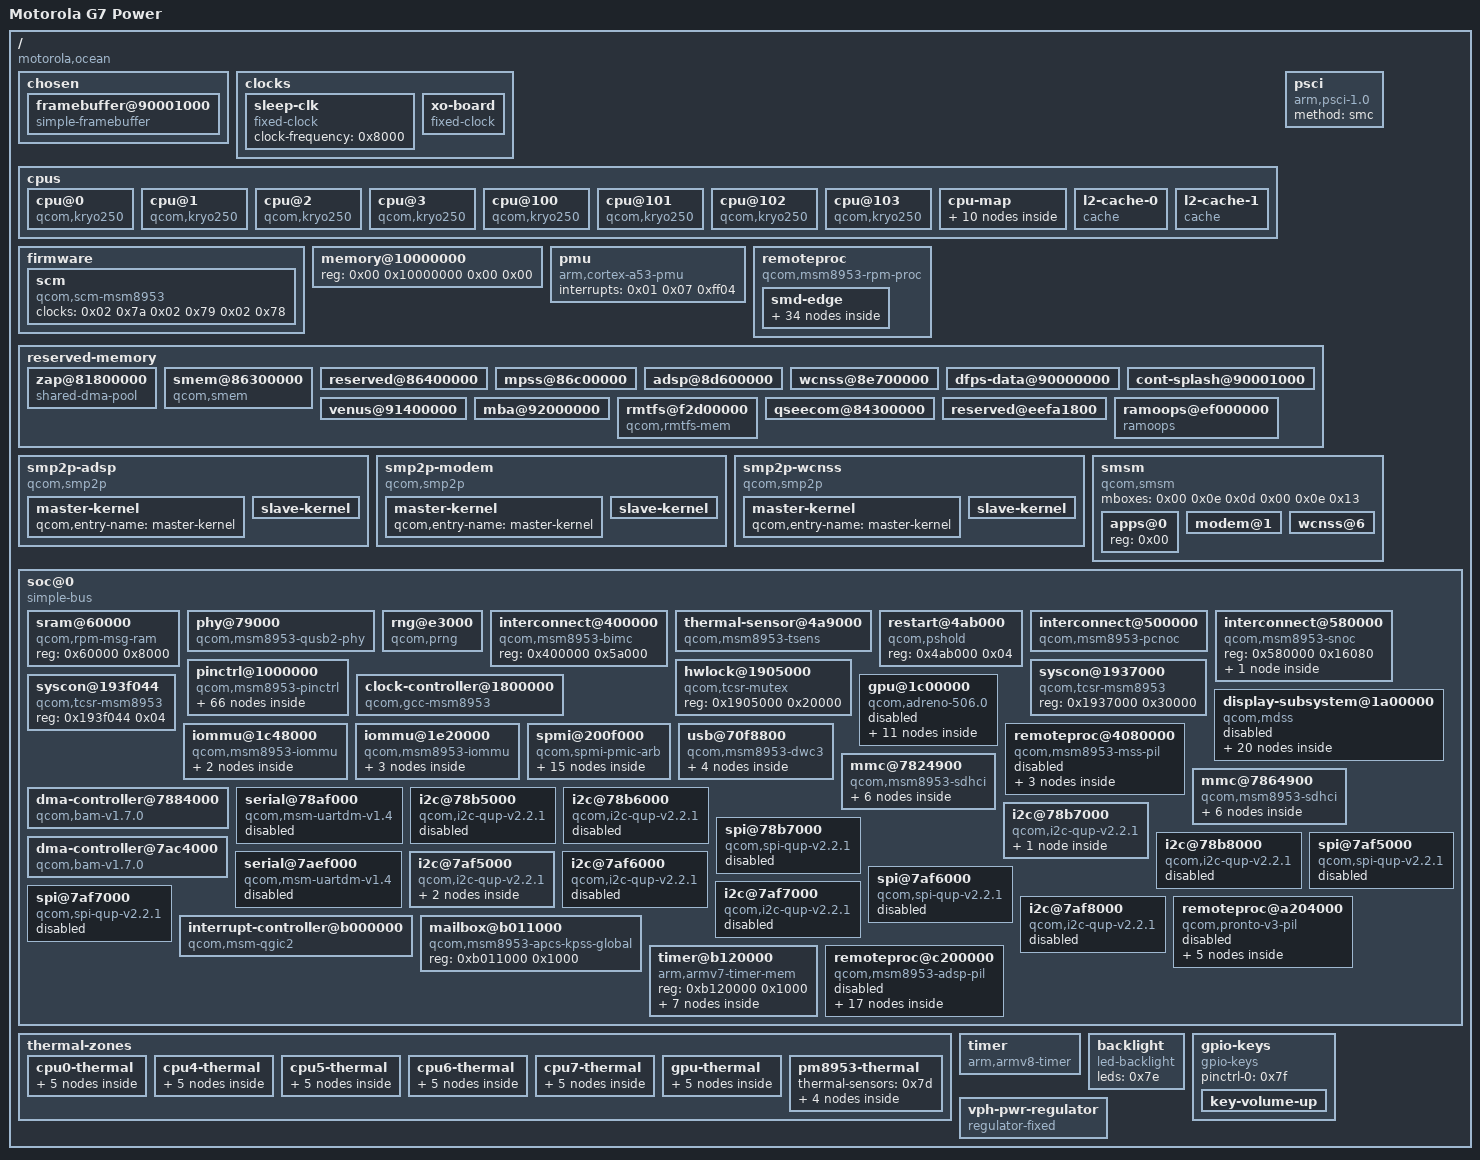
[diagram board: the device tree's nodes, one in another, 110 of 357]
/dts-v1/;

/ {
	interrupt-parent = <0x01>;
	#address-cells = <0x02>;
	#size-cells = <0x02>;
	model = "Motorola G7 Power";
	compatible = "motorola,ocean\0qcom,sdm632";
	chassis-type = "handset";
	qcom,msm-id = <0x15d 0x00>;
	qcom,board-id = <0x141 0xc100>;
	qcom,pmic-id = <0x10016 0x25 0x00 0x00>;

	chosen {
		#address-cells = <0x02>;
		#size-cells = <0x02>;
		ranges;

		framebuffer@90001000 {
			compatible = "simple-framebuffer";
			reg = <0x00 0x90001000 0x00 0x321900>;
			width = <0x2d0>;
			height = <0x5f0>;
			stride = <0x870>;
			format = "r8g8b8";
			power-domains = <0x02 0x02>;
			clocks = <0x02 0x81 0x02 0x82 0x02 0x8a 0x02 0x87 0x02 0x83 0x02 0x88 0x02 0x85>;
		};
	};

	clocks {

		sleep-clk {
			compatible = "fixed-clock";
			#clock-cells = <0x00>;
			clock-frequency = <0x8000>;
			phandle = <0x1c>;
		};

		xo-board {
			compatible = "fixed-clock";
			#clock-cells = <0x00>;
			clock-frequency = <0x124f800>;
			clock-output-names = "xo";
			phandle = <0x0f>;
		};
	};

	cpus {
		#address-cells = <0x01>;
		#size-cells = <0x00>;

		cpu@0 {
			device_type = "cpu";
			compatible = "qcom,kryo250";
			reg = <0x00>;
			enable-method = "psci";
			capacity-dmips-mhz = <0x400>;
			interconnects = <0x03 0x00 0x01 0x03 0x06 0x01>;
			next-level-cache = <0x04>;
			#cooling-cells = <0x02>;
			phandle = <0x06>;
		};

		cpu@1 {
			device_type = "cpu";
			compatible = "qcom,kryo250";
			reg = <0x01>;
			enable-method = "psci";
			capacity-dmips-mhz = <0x400>;
			interconnects = <0x03 0x00 0x01 0x03 0x06 0x01>;
			next-level-cache = <0x04>;
			#cooling-cells = <0x02>;
			phandle = <0x07>;
		};

		cpu@2 {
			device_type = "cpu";
			compatible = "qcom,kryo250";
			reg = <0x02>;
			enable-method = "psci";
			capacity-dmips-mhz = <0x400>;
			interconnects = <0x03 0x00 0x01 0x03 0x06 0x01>;
			next-level-cache = <0x04>;
			#cooling-cells = <0x02>;
			phandle = <0x08>;
		};

		cpu@3 {
			device_type = "cpu";
			compatible = "qcom,kryo250";
			reg = <0x03>;
			enable-method = "psci";
			capacity-dmips-mhz = <0x400>;
			interconnects = <0x03 0x00 0x01 0x03 0x06 0x01>;
			next-level-cache = <0x04>;
			#cooling-cells = <0x02>;
			phandle = <0x09>;
		};

		cpu@100 {
			device_type = "cpu";
			compatible = "qcom,kryo250";
			reg = <0x100>;
			enable-method = "psci";
			capacity-dmips-mhz = <0x7bc>;
			interconnects = <0x03 0x00 0x01 0x03 0x06 0x01>;
			next-level-cache = <0x05>;
			#cooling-cells = <0x02>;
			phandle = <0x0a>;
		};

		cpu@101 {
			device_type = "cpu";
			compatible = "qcom,kryo250";
			reg = <0x101>;
			enable-method = "psci";
			capacity-dmips-mhz = <0x7bc>;
			interconnects = <0x03 0x00 0x01 0x03 0x06 0x01>;
			next-level-cache = <0x05>;
			#cooling-cells = <0x02>;
			phandle = <0x0b>;
		};

		cpu@102 {
			device_type = "cpu";
			compatible = "qcom,kryo250";
			reg = <0x102>;
			enable-method = "psci";
			capacity-dmips-mhz = <0x7bc>;
			interconnects = <0x03 0x00 0x01 0x03 0x06 0x01>;
			next-level-cache = <0x05>;
			#cooling-cells = <0x02>;
			phandle = <0x0c>;
		};

		cpu@103 {
			device_type = "cpu";
			compatible = "qcom,kryo250";
			reg = <0x103>;
			enable-method = "psci";
			capacity-dmips-mhz = <0x7bc>;
			interconnects = <0x03 0x00 0x01 0x03 0x06 0x01>;
			next-level-cache = <0x05>;
			#cooling-cells = <0x02>;
			phandle = <0x0d>;
		};

		cpu-map {

			cluster0 {

				core0 {
					cpu = <0x06>;
				};

				core1 {
					cpu = <0x07>;
				};

				core2 {
					cpu = <0x08>;
				};

				core3 {
					cpu = <0x09>;
				};
			};

			cluster1 {

				core0 {
					cpu = <0x0a>;
				};

				core1 {
					cpu = <0x0b>;
				};

				core2 {
					cpu = <0x0c>;
				};

				core3 {
					cpu = <0x0d>;
				};
			};
		};

		l2-cache-0 {
			compatible = "cache";
			cache-level = <0x02>;
			cache-unified;
			phandle = <0x04>;
		};

		l2-cache-1 {
			compatible = "cache";
			cache-level = <0x02>;
			cache-unified;
			phandle = <0x05>;
		};
	};

	firmware {

		scm {
			compatible = "qcom,scm-msm8953\0qcom,scm";
			clocks = <0x02 0x7a 0x02 0x79 0x02 0x78>;
			clock-names = "core\0bus\0iface";
			#reset-cells = <0x01>;
		};
	};

	memory@10000000 {
		device_type = "memory";
		reg = <0x00 0x10000000 0x00 0x00>;
	};

	pmu {
		compatible = "arm,cortex-a53-pmu";
		interrupts = <0x01 0x07 0xff04>;
	};

	psci {
		compatible = "arm,psci-1.0";
		method = "smc";
	};

	remoteproc {
		compatible = "qcom,msm8953-rpm-proc\0qcom,rpm-proc";

		smd-edge {
			interrupts = <0x00 0xa8 0x01>;
			mboxes = <0x0e 0x00>;
			qcom,smd-edge = <0x0f>;

			rpm-requests {
				compatible = "qcom,rpm-msm8953\0qcom,smd-rpm";
				qcom,smd-channels = "rpm_requests";

				clock-controller {
					compatible = "qcom,rpmcc-msm8953\0qcom,rpmcc";
					clocks = <0x0f>;
					clock-names = "xo";
					#clock-cells = <0x01>;
					phandle = <0x1b>;
				};

				power-controller {
					compatible = "qcom,msm8953-rpmpd";
					#power-domain-cells = <0x01>;
					operating-points-v2 = <0x10>;
					phandle = <0x34>;

					opp-table {
						compatible = "operating-points-v2";
						phandle = <0x10>;

						opp1 {
							opp-level = <0x10>;
						};

						opp2 {
							opp-level = <0x20>;
						};

						opp3 {
							opp-level = <0x30>;
							phandle = <0x2a>;
						};

						opp4 {
							opp-level = <0x40>;
							phandle = <0x2b>;
						};

						opp5 {
							opp-level = <0x80>;
							phandle = <0x2c>;
						};

						opp6 {
							opp-level = <0xc0>;
							phandle = <0x2d>;
						};

						opp7 {
							opp-level = <0x100>;
							phandle = <0x2e>;
						};

						opp8 {
							opp-level = <0x140>;
							phandle = <0x2f>;
						};

						opp9 {
							opp-level = <0x180>;
							phandle = <0x30>;
						};
					};
				};

				regulators {
					compatible = "qcom,rpm-pm8953-regulators";
					vdd_l1-supply = <0x11>;
					vdd_l2_l3-supply = <0x11>;
					vdd_l4_l5_l6_l7_l16_l19-supply = <0x12>;
					vdd_l8_l11_l12_l13_l14_l15-supply = <0x13>;
					vdd_l9_l10_l17_l18_l22-supply = <0x13>;

					s3 {
						regulator-min-microvolt = <0xf03c0>;
						regulator-max-microvolt = <0x12ebc0>;
						phandle = <0x11>;
					};

					s4 {
						regulator-min-microvolt = <0xfcee0>;
						regulator-max-microvolt = <0x1f20c0>;
						phandle = <0x12>;
					};

					l1 {
						regulator-min-microvolt = <0xee098>;
						regulator-max-microvolt = <0x100590>;
					};

					l2 {
						regulator-min-microvolt = <0xee098>;
						regulator-max-microvolt = <0x11edd8>;
					};

					l3 {
						regulator-min-microvolt = <0xe1d48>;
						regulator-max-microvolt = <0xe1d48>;
						regulator-allow-set-load;
						phandle = <0x17>;
					};

					l5 {
						regulator-min-microvolt = <0x1b7740>;
						regulator-max-microvolt = <0x1b7740>;
						phandle = <0x44>;
					};

					l6 {
						regulator-min-microvolt = <0x1b7740>;
						regulator-max-microvolt = <0x1b7740>;
						regulator-always-on;
						regulator-boot-on;
					};

					l7 {
						regulator-min-microvolt = <0x1b7740>;
						regulator-max-microvolt = <0x1cfde0>;
						phandle = <0x18>;
					};

					l8 {
						regulator-min-microvolt = <0x2c4020>;
						regulator-max-microvolt = <0x2c4020>;
						phandle = <0x43>;
					};

					l9 {
						regulator-min-microvolt = <0x2dc6c0>;
						regulator-max-microvolt = <0x325aa0>;
					};

					l10 {
						regulator-min-microvolt = <0x2ab980>;
						regulator-max-microvolt = <0x2dc6c0>;
					};

					l11 {
						regulator-min-microvolt = <0x2d0370>;
						regulator-max-microvolt = <0x2d0370>;
						phandle = <0x4e>;
					};

					l12 {
						regulator-min-microvolt = <0x1b7740>;
						regulator-max-microvolt = <0x2d0370>;
						phandle = <0x4f>;
					};

					l13 {
						regulator-min-microvolt = <0x2faf08>;
						regulator-max-microvolt = <0x2faf08>;
						phandle = <0x19>;
					};

					l16 {
						regulator-min-microvolt = <0x1b7740>;
						regulator-max-microvolt = <0x1b7740>;
					};

					l17 {
						regulator-min-microvolt = <0x2b7cd0>;
						regulator-max-microvolt = <0x2b7cd0>;
					};

					l18 {
						regulator-min-microvolt = <0x1b7740>;
						regulator-max-microvolt = <0x2932e0>;
						regulator-always-on;
						regulator-boot-on;
					};

					l19 {
						regulator-min-microvolt = <0x124f80>;
						regulator-max-microvolt = <0x149970>;
					};

					l22 {
						regulator-min-microvolt = <0x1b7740>;
						regulator-max-microvolt = <0x1b7740>;
						regulator-always-on;
					};

					l23 {
						regulator-min-microvolt = <0xee098>;
						regulator-max-microvolt = <0x12b128>;
					};
				};
			};
		};
	};

	reserved-memory {
		#address-cells = <0x02>;
		#size-cells = <0x02>;
		ranges;

		zap@81800000 {
			compatible = "shared-dma-pool";
			reg = <0x00 0x81800000 0x00 0x2000>;
			no-map;
			phandle = <0x29>;
		};

		smem@86300000 {
			compatible = "qcom,smem";
			reg = <0x00 0x86300000 0x00 0x100000>;
			qcom,rpm-msg-ram = <0x14>;
			hwlocks = <0x15 0x03>;
			no-map;
		};

		reserved@86400000 {
			reg = <0x00 0x86400000 0x00 0x400000>;
			no-map;
		};

		mpss@86c00000 {
			reg = <0x00 0x86c00000 0x00 0x6a00000>;
			no-map;
			phandle = <0x38>;
		};

		adsp@8d600000 {
			reg = <0x00 0x8d600000 0x00 0x1100000>;
			no-map;
			phandle = <0x73>;
		};

		wcnss@8e700000 {
			reg = <0x00 0x8e700000 0x00 0x700000>;
			no-map;
			phandle = <0x6c>;
		};

		dfps-data@90000000 {
			reg = <0x00 0x90000000 0x00 0x1000>;
			no-map;
		};

		cont-splash@90001000 {
			reg = <0x00 0x90001000 0x00 0x321900>;
			no-map;
		};

		venus@91400000 {
			reg = <0x00 0x91400000 0x00 0x700000>;
			no-map;
		};

		mba@92000000 {
			reg = <0x00 0x92000000 0x00 0x100000>;
			no-map;
			phandle = <0x37>;
		};

		rmtfs@f2d00000 {
			compatible = "qcom,rmtfs-mem";
			reg = <0x00 0xf2d00000 0x00 0x180000>;
			no-map;
			qcom,client-id = <0x01>;
		};

		qseecom@84300000 {
			reg = <0x00 0x84300000 0x00 0x2000000>;
			no-map;
		};

		reserved@eefa1800 {
			reg = <0x00 0xeefa1800 0x00 0x5e800>;
			no-map;
		};

		ramoops@ef000000 {
			compatible = "ramoops";
			reg = <0x00 0xef000000 0x00 0xbf800>;
			console-size = <0x40000>;
			pmsg-size = <0x40000>;
			record-size = <0x3f800>;
		};
	};

	smp2p-adsp {
		compatible = "qcom,smp2p";
		qcom,smem = <0x1bb 0x1ad>;
		interrupts = <0x00 0x123 0x01>;
		mboxes = <0x0e 0x0a>;
		qcom,local-pid = <0x00>;
		qcom,remote-pid = <0x02>;

		master-kernel {
			qcom,entry-name = "master-kernel";
			#qcom,smem-state-cells = <0x01>;
			phandle = <0x74>;
		};

		slave-kernel {
			qcom,entry-name = "slave-kernel";
			interrupt-controller;
			#interrupt-cells = <0x02>;
			phandle = <0x72>;
		};
	};

	smp2p-modem {
		compatible = "qcom,smp2p";
		qcom,smem = <0x1b3 0x1ac>;
		interrupts = <0x00 0x1b 0x01>;
		mboxes = <0x0e 0x0e>;
		qcom,local-pid = <0x00>;
		qcom,remote-pid = <0x01>;

		master-kernel {
			qcom,entry-name = "master-kernel";
			#qcom,smem-state-cells = <0x01>;
			phandle = <0x35>;
		};

		slave-kernel {
			qcom,entry-name = "slave-kernel";
			interrupt-controller;
			#interrupt-cells = <0x02>;
			phandle = <0x33>;
		};
	};

	smp2p-wcnss {
		compatible = "qcom,smp2p";
		qcom,smem = <0x1c3 0x1af>;
		interrupts = <0x00 0x8f 0x01>;
		mboxes = <0x0e 0x12>;
		qcom,local-pid = <0x00>;
		qcom,remote-pid = <0x04>;

		master-kernel {
			qcom,entry-name = "master-kernel";
			#qcom,smem-state-cells = <0x01>;
			phandle = <0x6e>;
		};

		slave-kernel {
			qcom,entry-name = "slave-kernel";
			interrupt-controller;
			#interrupt-cells = <0x02>;
			phandle = <0x6d>;
		};
	};

	smsm {
		compatible = "qcom,smsm";
		#address-cells = <0x01>;
		#size-cells = <0x00>;
		mboxes = <0x00 0x0e 0x0d 0x00 0x0e 0x13>;

		apps@0 {
			reg = <0x00>;
			#qcom,smem-state-cells = <0x01>;
			phandle = <0x71>;
		};

		modem@1 {
			reg = <0x01>;
			interrupts = <0x00 0x1a 0x01>;
			interrupt-controller;
			#interrupt-cells = <0x02>;
		};

		wcnss@6 {
			reg = <0x06>;
			interrupts = <0x00 0x90 0x01>;
			interrupt-controller;
			#interrupt-cells = <0x02>;
		};
	};

	soc@0 {
		#address-cells = <0x01>;
		#size-cells = <0x01>;
		ranges = <0x00 0x00 0x00 0xffffffff>;
		compatible = "simple-bus";

		sram@60000 {
			compatible = "qcom,rpm-msg-ram";
			reg = <0x60000 0x8000>;
			phandle = <0x14>;
		};

		phy@79000 {
			compatible = "qcom,msm8953-qusb2-phy";
			reg = <0x79000 0x180>;
			#phy-cells = <0x00>;
			clocks = <0x02 0xa3 0x02 0x96>;
			clock-names = "cfg_ahb\0ref";
			qcom,tcsr-syscon = <0x16>;
			resets = <0x02 0x02>;
			status = "okay";
			vdd-supply = <0x17>;
			vdda-pll-supply = <0x18>;
			vdda-phy-dpdm-supply = <0x19>;
			phandle = <0x39>;
		};

		rng@e3000 {
			compatible = "qcom,prng";
			reg = <0xe3000 0x1000>;
			clocks = <0x02 0x94>;
			clock-names = "core";
		};

		interconnect@400000 {
			compatible = "qcom,msm8953-bimc";
			reg = <0x400000 0x5a000>;
			#interconnect-cells = <0x02>;
			phandle = <0x03>;
		};

		thermal-sensor@4a9000 {
			compatible = "qcom,msm8953-tsens\0qcom,tsens-v2";
			reg = <0x4a9000 0x1000 0x4a8000 0x1000>;
			#qcom,sensors = <0x10>;
			interrupts = <0x00 0xb8 0x04 0x00 0x13a 0x04>;
			interrupt-names = "uplow\0critical";
			#thermal-sensor-cells = <0x01>;
			phandle = <0x75>;
		};

		restart@4ab000 {
			compatible = "qcom,pshold";
			reg = <0x4ab000 0x04>;
		};

		interconnect@500000 {
			compatible = "qcom,msm8953-pcnoc";
			reg = <0x500000 0x12080>;
			clocks = <0x02 0x91>;
			clock-names = "pcnoc_usb3_axi";
			#interconnect-cells = <0x02>;
			phandle = <0x20>;
		};

		interconnect@580000 {
			compatible = "qcom,msm8953-snoc";
			reg = <0x580000 0x16080>;
			#interconnect-cells = <0x02>;

			interconnect-snoc {
				compatible = "qcom,msm8953-snoc-mm";
				#interconnect-cells = <0x02>;
				phandle = <0x1f>;
			};
		};

		pinctrl@1000000 {
			compatible = "qcom,msm8953-pinctrl";
			reg = <0x1000000 0x300000>;
			interrupts = <0x00 0xd0 0x04>;
			gpio-controller;
			gpio-ranges = <0x1a 0x00 0x00 0x8e>;
			#gpio-cells = <0x02>;
			interrupt-controller;
			#interrupt-cells = <0x02>;
			gpio-reserved-ranges = <0x60 0x04>;
			phandle = <0x1a>;

			uart-console-active-state {
				pins = "gpio4\0gpio5";
				function = "blsp_uart2";
				drive-strength = <0x02>;
				bias-disable;
			};

			uart-console-sleep-state {
				pins = "gpio4\0gpio5";
				function = "blsp_uart2";
				drive-strength = <0x02>;
				bias-pull-down;
			};

			sdc1-clk-on-state {
				pins = "sdc1_clk";
				bias-disable;
				drive-strength = <0x10>;
				phandle = <0x3b>;
			};

			sdc1-clk-off-state {
				pins = "sdc1_clk";
				bias-disable;
				drive-strength = <0x02>;
				phandle = <0x3f>;
			};

			sdc1-cmd-on-state {
				pins = "sdc1_cmd";
				bias-disable;
				drive-strength = <0x0a>;
				phandle = <0x3c>;
			};

			sdc1-cmd-off-state {
				pins = "sdc1_cmd";
				bias-disable;
				drive-strength = <0x02>;
				phandle = <0x40>;
			};

			sdc1-data-on-state {
				pins = "sdc1_data";
				bias-pull-up;
				drive-strength = <0x0a>;
				phandle = <0x3d>;
			};

			sdc1-data-off-state {
				pins = "sdc1_data";
				bias-pull-up;
				drive-strength = <0x02>;
				phandle = <0x41>;
			};

			sdc1-rclk-on-state {
				pins = "sdc1_rclk";
				bias-pull-down;
				phandle = <0x3e>;
			};

			sdc1-rclk-off-state {
				pins = "sdc1_rclk";
				bias-pull-down;
				phandle = <0x42>;
			};

			sdc2-clk-on-state {
				pins = "sdc2_clk";
				drive-strength = <0x10>;
				bias-disable;
				phandle = <0x46>;
			};

			sdc2-clk-off-state {
				pins = "sdc2_clk";
				bias-disable;
				drive-strength = <0x02>;
				phandle = <0x4a>;
			};

			sdc2-cmd-on-state {
				pins = "sdc2_cmd";
				bias-pull-up;
				drive-strength = <0x0a>;
				phandle = <0x47>;
			};

			sdc2-cmd-off-state {
				pins = "sdc2_cmd";
				bias-pull-up;
				drive-strength = <0x02>;
				phandle = <0x4b>;
			};

			sdc2-data-on-state {
				pins = "sdc2_data";
				bias-pull-up;
				drive-strength = <0x0a>;
				phandle = <0x48>;
			};

			sdc2-data-off-state {
				pins = "sdc2_data";
				bias-pull-up;
				drive-strength = <0x02>;
				phandle = <0x4c>;
			};

			cd-on-state {
				pins = "gpio133";
				function = "gpio";
				drive-strength = <0x02>;
				bias-pull-up;
				phandle = <0x49>;
			};

			cd-off-state {
				pins = "gpio133";
				function = "gpio";
				drive-strength = <0x02>;
				bias-disable;
				phandle = <0x4d>;
			};

			gpio-key-default-state {
				pins = "gpio85";
				function = "gpio";
				drive-strength = <0x02>;
				bias-pull-up;
				phandle = <0x7f>;
			};

			i2c-1-default-state {
				pins = "gpio2\0gpio3";
				function = "blsp_i2c1";
				drive-strength = <0x02>;
				bias-disable;
				phandle = <0x51>;
			};

			i2c-1-sleep-state {
				pins = "gpio2\0gpio3";
				function = "gpio";
				drive-strength = <0x02>;
				bias-disable;
				phandle = <0x52>;
			};

			i2c-2-default-state {
				pins = "gpio6\0gpio7";
				function = "blsp_i2c2";
				drive-strength = <0x02>;
				bias-disable;
				phandle = <0x53>;
			};

			i2c-2-sleep-state {
				pins = "gpio6\0gpio7";
				function = "gpio";
				drive-strength = <0x02>;
				bias-disable;
				phandle = <0x54>;
			};

			i2c-3-default-state {
				pins = "gpio10\0gpio11";
				function = "blsp_i2c3";
				drive-strength = <0x02>;
				bias-disable;
				phandle = <0x55>;
			};

			i2c-3-sleep-state {
				pins = "gpio10\0gpio11";
				function = "gpio";
				drive-strength = <0x02>;
				bias-disable;
				phandle = <0x56>;
			};

			i2c-4-default-state {
				pins = "gpio14\0gpio15";
				function = "blsp_i2c4";
				drive-strength = <0x02>;
				bias-disable;
				phandle = <0x5a>;
			};

			i2c-4-sleep-state {
				pins = "gpio14\0gpio15";
				function = "gpio";
				drive-strength = <0x02>;
				bias-disable;
				phandle = <0x5b>;
			};

			i2c-5-default-state {
				pins = "gpio18\0gpio19";
				function = "blsp_i2c5";
				drive-strength = <0x02>;
				bias-disable;
				phandle = <0x5e>;
			};

			i2c-5-sleep-state {
				pins = "gpio18\0gpio19";
				function = "gpio";
				drive-strength = <0x02>;
				bias-disable;
				phandle = <0x5f>;
			};

			i2c-6-default-state {
				pins = "gpio22\0gpio23";
				function = "blsp_i2c6";
				drive-strength = <0x02>;
				bias-disable;
				phandle = <0x62>;
			};

			i2c-6-sleep-state {
				pins = "gpio22\0gpio23";
				function = "gpio";
				drive-strength = <0x02>;
				bias-disable;
				phandle = <0x63>;
			};

			i2c-7-default-state {
				pins = "gpio135\0gpio136";
				function = "blsp_i2c7";
				drive-strength = <0x02>;
				bias-disable;
				phandle = <0x66>;
			};

			i2c-7-sleep-state {
				pins = "gpio135\0gpio136";
				function = "gpio";
				drive-strength = <0x02>;
				bias-disable;
				phandle = <0x67>;
			};

			i2c-8-default-state {
				pins = "gpio98\0gpio99";
				function = "blsp_i2c8";
				drive-strength = <0x02>;
				bias-disable;
				phandle = <0x6a>;
			};

			i2c-8-sleep-state {
				pins = "gpio98\0gpio99";
				function = "gpio";
				drive-strength = <0x02>;
				bias-disable;
				phandle = <0x6b>;
			};

			spi-3-default-state {
				phandle = <0x57>;

				cs-pins {
					pins = "gpio10";
					function = "blsp_spi3";
					drive-strength = <0x02>;
					bias-disable;
				};

				spi-pins {
					pins = "gpio8\0gpio9\0gpio11";
					function = "blsp_spi3";
					drive-strength = <0x0c>;
					bias-disable;
				};
			};

			spi-3-sleep-state {
				phandle = <0x58>;

				cs-pins {
					pins = "gpio10";
					function = "gpio";
					drive-strength = <0x02>;
					bias-disable;
				};

				spi-pins {
					pins = "gpio8\0gpio9\0gpio11";
					function = "gpio";
					drive-strength = <0x02>;
					bias-pull-down;
				};
			};

			spi-5-default-state {
				phandle = <0x60>;

				cs-pins {
					pins = "gpio18";
					function = "blsp_spi5";
					drive-strength = <0x02>;
					bias-disable;
				};

				spi-pins {
					pins = "gpio16\0gpio17\0gpio19";
					function = "blsp_spi5";
					drive-strength = <0x0c>;
					bias-disable;
				};
			};

			spi-5-sleep-state {
				phandle = <0x61>;

				cs-pins {
					pins = "gpio18";
					function = "gpio";
					drive-strength = <0x02>;
					bias-disable;
				};

				spi-pins {
					pins = "gpio16\0gpio17\0gpio19";
					function = "gpio";
					drive-strength = <0x02>;
					bias-pull-down;
				};
			};

			spi-6-default-state {
				phandle = <0x64>;

				cs-pins {
					pins = "gpio22";
					function = "blsp_spi6";
					drive-strength = <0x02>;
					bias-disable;
				};

				spi-pins {
					pins = "gpio20\0gpio21\0gpio23";
					function = "blsp_spi6";
					drive-strength = <0x0c>;
					bias-disable;
				};
			};

			spi-6-sleep-state {
				phandle = <0x65>;

				cs-pins {
					pins = "gpio22";
					function = "gpio";
					drive-strength = <0x02>;
					bias-disable;
				};

				spi-pins {
					pins = "gpio20\0gpio21\0gpio23";
					function = "gpio";
					drive-strength = <0x02>;
					bias-pull-down;
				};
			};

			spi-7-default-state {
				phandle = <0x68>;

				cs-pins {
					pins = "gpio136";
					function = "blsp_spi7";
					drive-strength = <0x02>;
					bias-disable;
				};

				spi-pins {
					pins = "gpio135\0gpio137\0gpio138";
					function = "blsp_spi7";
					drive-strength = <0x0c>;
					bias-disable;
				};
			};

			spi-7-sleep-state {
				phandle = <0x69>;

				cs-pins {
					pins = "gpio136";
					function = "gpio";
					drive-strength = <0x02>;
					bias-disable;
				};

				spi-pins {
					pins = "gpio135\0gpio137\0gpio138";
					function = "gpio";
					drive-strength = <0x02>;
					bias-pull-down;
				};
			};

			uart-5-default-state {
				pins = "gpio16\0gpio17\0gpio18\0gpio19";
				function = "blsp_uart5";
				drive-strength = <0x10>;
				bias-disable;
				phandle = <0x5c>;
			};

			uart-5-sleep-state {
				pins = "gpio16\0gpio17\0gpio18\0gpio19";
				function = "gpio";
				drive-strength = <0x02>;
				bias-disable;
				phandle = <0x5d>;
			};

			wcnss-active-state {
				phandle = <0x6f>;

				wcss-wlan2-pins {
					pins = "gpio76";
					function = "wcss_wlan2";
					drive-strength = <0x06>;
					bias-pull-up;
				};

				wcss-wlan1-pins {
					pins = "gpio77";
					function = "wcss_wlan1";
					drive-strength = <0x06>;
					bias-pull-up;
				};

				wcss-wlan0-pins {
					pins = "gpio78";
					function = "wcss_wlan0";
					drive-strength = <0x06>;
					bias-pull-up;
				};

				wcss-wlan-pins {
					pins = "gpio79\0gpio80";
					function = "wcss_wlan";
					drive-strength = <0x06>;
					bias-pull-up;
				};
			};
		};

		clock-controller@1800000 {
			compatible = "qcom,gcc-msm8953";
			reg = <0x1800000 0x80000>;
			#clock-cells = <0x01>;
			#reset-cells = <0x01>;
			#power-domain-cells = <0x01>;
			clocks = <0x1b 0x00 0x1c 0x1d 0x01 0x1d 0x00 0x1e 0x01 0x1e 0x00>;
			clock-names = "xo\0sleep\0dsi0pll\0dsi0pllbyte\0dsi1pll\0dsi1pllbyte";
			phandle = <0x02>;
		};

		hwlock@1905000 {
			compatible = "qcom,tcsr-mutex";
			reg = <0x1905000 0x20000>;
			#hwlock-cells = <0x01>;
			phandle = <0x15>;
		};

		syscon@1937000 {
			compatible = "qcom,tcsr-msm8953\0syscon";
			reg = <0x1937000 0x30000>;
			phandle = <0x36>;
		};

		syscon@193f044 {
			compatible = "qcom,tcsr-msm8953\0syscon";
			reg = <0x193f044 0x04>;
			phandle = <0x16>;
		};

		display-subsystem@1a00000 {
			compatible = "qcom,mdss";
			reg = <0x1a00000 0x1000 0x1ab0000 0x1040>;
			reg-names = "mdss_phys\0vbif_phys";
			power-domains = <0x02 0x02>;
			interrupts = <0x00 0x48 0x04>;
			interrupt-controller;
			#interrupt-cells = <0x01>;
			interconnects = <0x1f 0x01 0x03 0x03 0x06 0x03 0x03 0x00 0x01 0x20 0x1f 0x01>;
			interconnect-names = "mdp0-mem\0cpu-cfg";
			clocks = <0x02 0x81 0x02 0x82 0x02 0x8a 0x02 0x87>;
			clock-names = "iface\0bus\0vsync\0core";
			resets = <0x02 0x06>;
			#address-cells = <0x01>;
			#size-cells = <0x01>;
			ranges;
			status = "disabled";
			phandle = <0x21>;

			display-controller@1a01000 {
				compatible = "qcom,msm8953-mdp5\0qcom,mdp5";
				reg = <0x1a01000 0x89000>;
				reg-names = "mdp_phys";
				interrupt-parent = <0x21>;
				interrupts = <0x00>;
				power-domains = <0x02 0x02>;
				clocks = <0x02 0x81 0x02 0x82 0x02 0x87 0x02 0x8a>;
				clock-names = "iface\0bus\0core\0vsync";
				iommus = <0x22 0x15>;

				ports {
					#address-cells = <0x01>;
					#size-cells = <0x00>;

					port@0 {
						reg = <0x00>;

						endpoint {
							remote-endpoint = <0x23>;
							phandle = <0x25>;
						};
					};

					port@1 {
						reg = <0x01>;

						endpoint {
							remote-endpoint = <0x24>;
							phandle = <0x26>;
						};
					};
				};
			};

			dsi@1a94000 {
				compatible = "qcom,msm8953-dsi-ctrl\0qcom,mdss-dsi-ctrl";
				reg = <0x1a94000 0x400>;
				reg-names = "dsi_ctrl";
				interrupt-parent = <0x21>;
				interrupts = <0x04>;
				assigned-clocks = <0x02 0x17 0x02 0xc0>;
				assigned-clock-parents = <0x1d 0x00 0x1d 0x01>;
				clocks = <0x02 0x87 0x02 0x81 0x02 0x82 0x02 0x83 0x02 0x88 0x02 0x85>;
				clock-names = "mdp_core\0iface\0bus\0byte\0pixel\0core";
				phys = <0x1d>;
				#address-cells = <0x01>;
				#size-cells = <0x00>;
				status = "disabled";

				ports {
					#address-cells = <0x01>;
					#size-cells = <0x00>;

					port@0 {
						reg = <0x00>;

						endpoint {
							remote-endpoint = <0x25>;
							phandle = <0x23>;
						};
					};

					port@1 {
						reg = <0x01>;

						endpoint {
						};
					};
				};
			};

			phy@1a94400 {
				compatible = "qcom,dsi-phy-14nm-8953";
				reg = <0x1a94400 0x100 0x1a94500 0x300 0x1a94800 0x188>;
				reg-names = "dsi_phy\0dsi_phy_lane\0dsi_pll";
				#clock-cells = <0x01>;
				#phy-cells = <0x00>;
				clocks = <0x02 0x81 0x1b 0x00>;
				clock-names = "iface\0ref";
				status = "disabled";
				phandle = <0x1d>;
			};

			dsi@1a96000 {
				compatible = "qcom,msm8953-dsi-ctrl\0qcom,mdss-dsi-ctrl";
				reg = <0x1a96000 0x400>;
				reg-names = "dsi_ctrl";
				interrupt-parent = <0x21>;
				interrupts = <0x05>;
				assigned-clocks = <0x02 0x18 0x02 0xc1>;
				assigned-clock-parents = <0x1e 0x00 0x1e 0x01>;
				clocks = <0x02 0x87 0x02 0x81 0x02 0x82 0x02 0x84 0x02 0x89 0x02 0x86>;
				clock-names = "mdp_core\0iface\0bus\0byte\0pixel\0core";
				phys = <0x1e>;
				status = "disabled";

				ports {
					#address-cells = <0x01>;
					#size-cells = <0x00>;

					port@0 {
						reg = <0x00>;

						endpoint {
							remote-endpoint = <0x26>;
							phandle = <0x24>;
						};
					};

					port@1 {
						reg = <0x01>;

						endpoint {
						};
					};
				};
			};

			phy@1a96400 {
				compatible = "qcom,dsi-phy-14nm-8953";
				reg = <0x1a96400 0x100 0x1a96500 0x300 0x1a96800 0x188>;
				reg-names = "dsi_phy\0dsi_phy_lane\0dsi_pll";
				#clock-cells = <0x01>;
				#phy-cells = <0x00>;
				clocks = <0x02 0x81 0x1b 0x00>;
				clock-names = "iface\0ref";
				status = "disabled";
				phandle = <0x1e>;
			};
		};

		gpu@1c00000 {
			compatible = "qcom,adreno-506.0\0qcom,adreno";
			reg = <0x1c00000 0x40000>;
			reg-names = "kgsl_3d0_reg_memory";
			interrupts = <0x00 0x21 0x04>;
			clocks = <0x02 0x8f 0x02 0x8d 0x02 0x2f 0x02 0x30 0x02 0x90 0x02 0x8e>;
			clock-names = "core\0iface\0mem_iface\0alt_mem_iface\0rbbmtimer\0alwayson";
			power-domains = <0x02 0x04>;
			interconnects = <0x03 0x01 0x03 0x03 0x06 0x03 0x03 0x00 0x01 0x20 0x21 0x01>;
			iommus = <0x27 0x00>;
			operating-points-v2 = <0x28>;
			#cooling-cells = <0x02>;
			status = "disabled";
			phandle = <0x7c>;

			zap-shader {
				memory-region = <0x29>;
			};

			opp-table {
				compatible = "operating-points-v2";
				phandle = <0x28>;

				opp-19200000 {
					opp-hz = <0x00 0x124f800>;
					opp-supported-hw = <0xff>;
					required-opps = <0x2a>;
				};

				opp-133300000 {
					opp-hz = <0x00 0x7f1ff20>;
					opp-supported-hw = <0xff>;
					required-opps = <0x2a>;
				};

				opp-216000000 {
					opp-hz = <0x00 0xcdfe600>;
					opp-supported-hw = <0xff>;
					required-opps = <0x2b>;
				};

				opp-320000000 {
					opp-hz = <0x00 0x1312d000>;
					opp-supported-hw = <0xff>;
					required-opps = <0x2c>;
				};

				opp-400000000 {
					opp-hz = <0x00 0x17d78400>;
					opp-supported-hw = <0xff>;
					required-opps = <0x2d>;
				};

				opp-510000000 {
					opp-hz = <0x00 0x1e65fb80>;
					opp-supported-hw = <0xff>;
					required-opps = <0x2e>;
				};

				opp-560000000 {
					opp-hz = <0x00 0x2160ec00>;
					opp-supported-hw = <0xff>;
					required-opps = <0x2f>;
				};

				opp-650000000 {
					opp-hz = <0x00 0x26be3680>;
					opp-supported-hw = <0xff>;
					required-opps = <0x30>;
				};

				opp-725000000 {
					opp-hz = <0x00 0x2b369f40>;
					opp-supported-hw = <0xff>;
					required-opps = <0x30>;
				};
			};
		};

		iommu@1c48000 {
			compatible = "qcom,msm8953-iommu\0qcom,msm-iommu-v2";
			ranges = <0x00 0x1c48000 0x8000>;
			clocks = <0x02 0x8d 0x02 0x2f>;
			clock-names = "iface\0bus";
			power-domains = <0x02 0x03>;
			qcom,iommu-secure-id = <0x12>;
			#address-cells = <0x01>;
			#iommu-cells = <0x01>;
			#size-cells = <0x01>;
			phandle = <0x27>;

			iommu-ctx@0 {
				compatible = "qcom,msm-iommu-v2-ns";
				reg = <0x00 0x1000>;
				interrupts = <0x00 0xe1 0x04>;
			};

			iommu-ctx@2000 {
				compatible = "qcom,msm-iommu-v2-sec";
				reg = <0x2000 0x1000>;
				interrupts = <0x00 0xe9 0x04>;
			};
		};

		iommu@1e20000 {
			compatible = "qcom,msm8953-iommu\0qcom,msm-iommu-v1";
			ranges = <0x00 0x1e20000 0x20000>;
			clocks = <0x02 0x9d 0x02 0x2e>;
			clock-names = "iface\0bus";
			qcom,iommu-secure-id = <0x11>;
			#address-cells = <0x01>;
			#iommu-cells = <0x01>;
			#size-cells = <0x01>;
			phandle = <0x22>;

			iommu-ctx@14000 {
				compatible = "qcom,msm-iommu-v1-ns";
				reg = <0x14000 0x1000>;
				interrupts = <0x00 0x6f 0x04>;
			};

			iommu-ctx@15000 {
				compatible = "qcom,msm-iommu-v1-ns";
				reg = <0x15000 0x1000>;
				interrupts = <0x00 0x70 0x04>;
			};

			iommu-ctx@16000 {
				compatible = "qcom,msm-iommu-v1-ns";
				reg = <0x16000 0x1000>;
				interrupts = <0x00 0x71 0x04>;
			};
		};

		spmi@200f000 {
			compatible = "qcom,spmi-pmic-arb";
			reg = <0x200f000 0x1000 0x2400000 0x800000 0x2c00000 0x800000 0x3800000 0x200000 0x200a000 0x2100>;
			reg-names = "core\0chnls\0obsrvr\0intr\0cnfg";
			interrupt-names = "periph_irq";
			interrupts = <0x00 0xbe 0x04>;
			qcom,ee = <0x00>;
			qcom,channel = <0x00>;
			interrupt-controller;
			#interrupt-cells = <0x04>;
			#address-cells = <0x02>;
			#size-cells = <0x00>;

			pmic@0 {
				compatible = "qcom,pm8953\0qcom,spmi-pmic";
				reg = <0x00 0x00>;
				#address-cells = <0x01>;
				#size-cells = <0x00>;

				pon@800 {
					compatible = "qcom,pm8916-pon";
					reg = <0x800>;
					mode-bootloader = <0x02>;
					mode-recovery = <0x01>;

					pwrkey {
						compatible = "qcom,pm8941-pwrkey";
						interrupts = <0x00 0x08 0x00 0x03>;
						debounce = <0x3d09>;
						bias-pull-up;
						linux,code = <0x74>;
					};

					resin {
						compatible = "qcom,pm8941-resin";
						interrupts = <0x00 0x08 0x01 0x03>;
						debounce = <0x3d09>;
						bias-pull-up;
						status = "okay";
						linux,code = <0x72>;
					};
				};

				temp-alarm@2400 {
					compatible = "qcom,spmi-temp-alarm";
					reg = <0x2400>;
					interrupts = <0x00 0x24 0x00 0x01>;
					io-channels = <0x31 0x08>;
					io-channel-names = "thermal";
					#thermal-sensor-cells = <0x00>;
					phandle = <0x7d>;
				};

				adc@3100 {
					compatible = "qcom,spmi-vadc";
					reg = <0x3100>;
					interrupts = <0x00 0x31 0x00 0x01>;
					#address-cells = <0x01>;
					#size-cells = <0x00>;
					#io-channel-cells = <0x01>;
					phandle = <0x31>;

					channel@8 {
						reg = <0x08>;
					};

					channel@9 {
						reg = <0x09>;
					};

					channel@a {
						reg = <0x0a>;
					};

					channel@c {
						reg = <0x0c>;
					};

					channel@e {
						reg = <0x0e>;
					};

					channel@f {
						reg = <0x0f>;
					};
				};

				rtc@6000 {
					compatible = "qcom,pm8941-rtc";
					reg = <0x6000 0x6100>;
					reg-names = "rtc\0alarm";
					interrupts = <0x00 0x61 0x01 0x01>;
				};

				gpio@c000 {
					compatible = "qcom,pm8953-gpio\0qcom,spmi-gpio";
					reg = <0xc000>;
					gpio-controller;
					gpio-ranges = <0x32 0x00 0x00 0x08>;
					#gpio-cells = <0x02>;
					interrupt-controller;
					#interrupt-cells = <0x02>;
					phandle = <0x32>;
				};
			};

			pmic@1 {
				compatible = "qcom,pm8953\0qcom,spmi-pmic";
				reg = <0x01 0x00>;
				#address-cells = <0x01>;
				#size-cells = <0x00>;
			};
		};

		remoteproc@4080000 {
			compatible = "qcom,msm8953-mss-pil";
			reg = <0x4080000 0x100 0x4020000 0x40>;
			reg-names = "qdsp6\0rmb";
			interrupts-extended = <0x01 0x00 0x18 0x01 0x33 0x00 0x01 0x33 0x01 0x01 0x33 0x02 0x01 0x33 0x03 0x01>;
			interrupt-names = "wdog\0fatal\0ready\0handover\0stop-ack";
			power-domains = <0x34 0x02 0x34 0x05 0x34 0x00>;
			power-domain-names = "cx\0mx\0mss";
			clocks = <0x02 0x8b 0x02 0x8c 0x02 0x47 0x1b 0x00>;
			clock-names = "iface\0bus\0mem\0xo";
			qcom,smem-states = <0x35 0x00>;
			qcom,smem-state-names = "stop";
			resets = <0x02 0x01>;
			reset-names = "mss_restart";
			qcom,halt-regs = <0x36 0x18000 0x19000 0x1a000>;
			status = "disabled";

			mba {
				memory-region = <0x37>;
			};

			mpss {
				memory-region = <0x38>;
			};

			smd-edge {
				interrupts = <0x00 0x19 0x01>;
				qcom,smd-edge = <0x00>;
				mboxes = <0x0e 0x0c>;
				qcom,remote-pid = <0x01>;
				label = "modem";
			};
		};

		usb@70f8800 {
			compatible = "qcom,msm8953-dwc3\0qcom,dwc3";
			reg = <0x70f8800 0x400>;
			#address-cells = <0x01>;
			#size-cells = <0x01>;
			ranges;
			interrupts = <0x00 0x86 0x04 0x00 0x88 0x04 0x00 0xdc 0x04>;
			interrupt-names = "pwr_event\0qusb2_phy\0ss_phy_irq";
			clocks = <0x02 0xa3 0x02 0x9e 0x02 0x91 0x02 0xa0 0x02 0x9f>;
			clock-names = "cfg_noc\0core\0iface\0sleep\0mock_utmi";
			assigned-clocks = <0x02 0x9f 0x02 0x9e>;
			assigned-clock-rates = <0x124f800 0x7f27450>;
			interconnects = <0x20 0x03 0x03 0x03 0x06 0x03 0x03 0x00 0x01 0x20 0x26 0x01>;
			interconnect-names = "usb-ddr\0apps-usb";
			power-domains = <0x02 0x05>;
			qcom,select-utmi-as-pipe-clk;
			status = "okay";

			usb@7000000 {
				compatible = "snps,dwc3";
				reg = <0x7000000 0xcc00>;
				interrupts = <0x00 0x8c 0x04>;
				phys = <0x39>;
				phy-names = "usb2-phy";
				snps,usb2-gadget-lpm-disable;
				snps,dis-u1-entry-quirk;
				snps,dis-u2-entry-quirk;
				snps,is-utmi-l1-suspend;
				snps,hird-threshold = [00];
				maximum-speed = "high-speed";
				dr_mode = "peripheral";

				ports {
					#address-cells = <0x01>;
					#size-cells = <0x00>;

					port@0 {
						reg = <0x00>;

						endpoint {
						};
					};
				};
			};
		};

		mmc@7824900 {
			compatible = "qcom,msm8953-sdhci\0qcom,sdhci-msm-v4";
			reg = <0x7824900 0x500 0x7824000 0x800>;
			reg-names = "hc\0core";
			interrupts = <0x00 0x7b 0x04 0x00 0x8a 0x04>;
			interrupt-names = "hc_irq\0pwr_irq";
			clocks = <0x02 0x98 0x02 0x99 0x1b 0x00>;
			clock-names = "iface\0core\0xo";
			interconnects = <0x20 0x05 0x03 0x03 0x06 0x03 0x03 0x00 0x01 0x20 0x22 0x01>;
			interconnect-names = "sdhc-ddr\0cpu-sdhc";
			power-domains = <0x34 0x02>;
			operating-points-v2 = <0x3a>;
			pinctrl-names = "default\0sleep";
			pinctrl-0 = <0x3b 0x3c 0x3d 0x3e>;
			pinctrl-1 = <0x3f 0x40 0x41 0x42>;
			mmc-hs400-1_8v;
			mmc-hs200-1_8v;
			mmc-ddr-1_8v;
			bus-width = <0x08>;
			non-removable;
			status = "okay";
			vmmc-supply = <0x43>;
			vqmmc-supply = <0x44>;

			opp-table-sdhc1 {
				compatible = "operating-points-v2";
				phandle = <0x3a>;

				opp-25000000 {
					opp-hz = <0x00 0x17d7840>;
					opp-peak-kBps = <0x30d40 0x186a0>;
					opp-avg-kBps = <0xff50 0x8000>;
					required-opps = <0x2b>;
				};

				opp-50000000 {
					opp-hz = <0x00 0x2faf080>;
					opp-peak-kBps = <0x61a80 0x30d40>;
					opp-avg-kBps = <0x1fe9e 0xff50>;
					required-opps = <0x2c>;
				};

				opp-100000000 {
					opp-hz = <0x00 0x5f5e100>;
					opp-peak-kBps = <0x61a80 0x61a80>;
					opp-avg-kBps = <0x1fe9e 0xff50>;
					required-opps = <0x2c>;
				};

				opp-192000000 {
					opp-hz = <0x00 0xb71b000>;
					opp-peak-kBps = <0xc3500 0x927c0>;
					opp-avg-kBps = <0x3fd3e 0x1fe9e>;
					required-opps = <0x2e>;
				};

				opp-384000000 {
					opp-hz = <0x00 0x16e36000>;
					opp-peak-kBps = "\0\f5\0\0\f5";
					opp-avg-kBps = <0x3fd3e 0x493e0>;
					required-opps = <0x2e>;
				};
			};
		};

		mmc@7864900 {
			compatible = "qcom,msm8953-sdhci\0qcom,sdhci-msm-v4";
			reg = <0x7864900 0x500 0x7864000 0x800>;
			reg-names = "hc\0core";
			interrupts = <0x00 0x7d 0x04 0x00 0xdd 0x04>;
			interrupt-names = "hc_irq\0pwr_irq";
			clocks = <0x02 0x9b 0x02 0x9c 0x1b 0x00>;
			clock-names = "iface\0core\0xo";
			interconnects = <0x20 0x06 0x03 0x03 0x06 0x03 0x03 0x00 0x01 0x20 0x23 0x01>;
			interconnect-names = "sdhc-ddr\0cpu-sdhc";
			power-domains = <0x34 0x02>;
			operating-points-v2 = <0x45>;
			pinctrl-names = "default\0sleep";
			pinctrl-0 = <0x46 0x47 0x48 0x49>;
			pinctrl-1 = <0x4a 0x4b 0x4c 0x4d>;
			bus-width = <0x04>;
			status = "okay";
			vmmc-supply = <0x4e>;
			vqmmc-supply = <0x4f>;

			opp-table-sdhc2 {
				compatible = "operating-points-v2";
				phandle = <0x45>;

				opp-25000000 {
					opp-hz = <0x00 0x17d7840>;
					opp-peak-kBps = <0x30d40 0x186a0>;
					opp-avg-kBps = <0xff50 0x8000>;
					required-opps = <0x2b>;
				};

				opp-50000000 {
					opp-hz = <0x00 0x2faf080>;
					opp-peak-kBps = <0x61a80 0x61a80>;
					opp-avg-kBps = <0x1fe9e 0xff50>;
					required-opps = <0x2c>;
				};

				opp-100000000 {
					opp-hz = <0x00 0x5f5e100>;
					opp-peak-kBps = <0xc3500 0x61a80>;
					opp-avg-kBps = <0x1fe9e 0x1fe9e>;
					required-opps = <0x2c>;
				};

				opp-177770000 {
					opp-hz = <0x00 0xa988e10>;
					opp-peak-kBps = <0x927c0 0x927c0>;
					opp-avg-kBps = <0x3fd3e 0x1fe9e>;
					required-opps = <0x2e>;
				};

				opp-200000000 {
					opp-hz = <0x00 0xbebc200>;
					opp-peak-kBps = "\0\f5\0\0\f5";
					opp-avg-kBps = <0x3fd3e 0x1fe9e>;
					required-opps = <0x2e>;
				};
			};
		};

		dma-controller@7884000 {
			compatible = "qcom,bam-v1.7.0";
			reg = <0x7884000 0x1f000>;
			interrupts = <0x00 0xee 0x04>;
			clocks = <0x02 0x31>;
			clock-names = "bam_clk";
			num-channels = <0x0c>;
			#dma-cells = <0x01>;
			qcom,ee = <0x00>;
			qcom,num-ees = <0x04>;
			qcom,controlled-remotely;
			phandle = <0x50>;
		};

		serial@78af000 {
			compatible = "qcom,msm-uartdm-v1.4\0qcom,msm-uartdm";
			reg = <0x78af000 0x200>;
			interrupts = <0x00 0x6b 0x04>;
			clocks = <0x02 0x3a 0x02 0x31>;
			clock-names = "core\0iface";
			status = "disabled";
		};

		i2c@78b5000 {
			compatible = "qcom,i2c-qup-v2.2.1";
			reg = <0x78b5000 0x600>;
			interrupts = <0x00 0x5f 0x04>;
			clock-names = "core\0iface";
			clocks = <0x02 0x32 0x02 0x31>;
			dmas = <0x50 0x04 0x50 0x05>;
			dma-names = "tx\0rx";
			pinctrl-names = "default\0sleep";
			pinctrl-0 = <0x51>;
			pinctrl-1 = <0x52>;
			#address-cells = <0x01>;
			#size-cells = <0x00>;
			status = "disabled";
		};

		i2c@78b6000 {
			compatible = "qcom,i2c-qup-v2.2.1";
			reg = <0x78b6000 0x600>;
			interrupts = <0x00 0x60 0x04>;
			clock-names = "core\0iface";
			clocks = <0x02 0x34 0x02 0x31>;
			dmas = <0x50 0x06 0x50 0x07>;
			dma-names = "tx\0rx";
			pinctrl-names = "default\0sleep";
			pinctrl-0 = <0x53>;
			pinctrl-1 = <0x54>;
			#address-cells = <0x01>;
			#size-cells = <0x00>;
			status = "disabled";
		};

		i2c@78b7000 {
			compatible = "qcom,i2c-qup-v2.2.1";
			reg = <0x78b7000 0x600>;
			interrupts = <0x00 0x61 0x04>;
			clock-names = "core\0iface";
			clocks = <0x02 0x36 0x02 0x31>;
			dmas = <0x50 0x08 0x50 0x09>;
			dma-names = "tx\0rx";
			pinctrl-names = "default\0sleep";
			pinctrl-0 = <0x55>;
			pinctrl-1 = <0x56>;
			#address-cells = <0x01>;
			#size-cells = <0x00>;
			status = "okay";

			touchscreen@41 {
				compatible = "ilitek,ili2117";
				reg = <0x41>;
				interrupt-parent = <0x1a>;
				interrupts = <0x41 0x02>;
				touchscreen-inverted-x;
			};
		};

		spi@78b7000 {
			compatible = "qcom,spi-qup-v2.2.1";
			reg = <0x78b7000 0x600>;
			interrupts = <0x00 0x61 0x04>;
			clock-names = "core\0iface";
			clocks = <0x02 0x37 0x02 0x31>;
			dmas = <0x50 0x08 0x50 0x09>;
			dma-names = "tx\0rx";
			pinctrl-names = "default\0sleep";
			pinctrl-0 = <0x57>;
			pinctrl-1 = <0x58>;
			#address-cells = <0x01>;
			#size-cells = <0x00>;
			status = "disabled";
		};

		i2c@78b8000 {
			compatible = "qcom,i2c-qup-v2.2.1";
			reg = <0x78b8000 0x600>;
			interrupts = <0x00 0x62 0x04>;
			clock-names = "core\0iface";
			clocks = <0x02 0x38 0x02 0x31>;
			dmas = <0x59 0x0a 0x59 0x0b>;
			dma-names = "tx\0rx";
			pinctrl-names = "default\0sleep";
			pinctrl-0 = <0x5a>;
			pinctrl-1 = <0x5b>;
			#address-cells = <0x01>;
			#size-cells = <0x00>;
			status = "disabled";
		};

		dma-controller@7ac4000 {
			compatible = "qcom,bam-v1.7.0";
			reg = <0x7ac4000 0x1f000>;
			interrupts = <0x00 0xef 0x04>;
			clocks = <0x02 0x3c>;
			clock-names = "bam_clk";
			num-channels = <0x0c>;
			#dma-cells = <0x01>;
			qcom,ee = <0x00>;
			qcom,num-ees = <0x04>;
			qcom,controlled-remotely;
			phandle = <0x59>;
		};

		serial@7aef000 {
			compatible = "qcom,msm-uartdm-v1.4\0qcom,msm-uartdm";
			reg = <0x7aef000 0x200>;
			interrupts = <0x00 0x132 0x04>;
			clocks = <0x02 0x45 0x02 0x3c>;
			clock-names = "core\0iface";
			dmas = <0x59 0x00 0x59 0x01>;
			dma-names = "tx\0rx";
			pinctrl-0 = <0x5c>;
			pinctrl-1 = <0x5d>;
			pinctrl-names = "default\0sleep";
			status = "disabled";
		};

		i2c@7af5000 {
			compatible = "qcom,i2c-qup-v2.2.1";
			reg = <0x7af5000 0x600>;
			interrupts = <0x00 0x12b 0x04>;
			clock-names = "core\0iface";
			clocks = <0x02 0x3d 0x02 0x3c>;
			dmas = <0x59 0x04 0x59 0x05>;
			dma-names = "tx\0rx";
			pinctrl-names = "default\0sleep";
			pinctrl-0 = <0x5e>;
			pinctrl-1 = <0x5f>;
			#address-cells = <0x01>;
			#size-cells = <0x00>;
			status = "okay";

			led-controller@36 {
				compatible = "ti,lm3697";
				reg = <0x36>;
				#address-cells = <0x01>;
				#size-cells = <0x00>;

				led@1 {
					reg = <0x01>;
					default-trigger = "backlight";
					function = "backlight";
					led-sources = <0x00 0x01 0x02>;
					phandle = <0x7e>;
				};
			};
		};

		spi@7af5000 {
			compatible = "qcom,spi-qup-v2.2.1";
			reg = <0x7af5000 0x600>;
			interrupts = <0x00 0x12b 0x04>;
			clock-names = "core\0iface";
			clocks = <0x02 0x3e 0x02 0x3c>;
			dmas = <0x59 0x04 0x59 0x05>;
			dma-names = "tx\0rx";
			pinctrl-names = "default\0sleep";
			pinctrl-0 = <0x60>;
			pinctrl-1 = <0x61>;
			#address-cells = <0x01>;
			#size-cells = <0x00>;
			status = "disabled";
		};

		i2c@7af6000 {
			compatible = "qcom,i2c-qup-v2.2.1";
			reg = <0x7af6000 0x600>;
			interrupts = <0x00 0x12c 0x04>;
			clock-names = "core\0iface";
			clocks = <0x02 0x3f 0x02 0x3c>;
			dmas = <0x59 0x06 0x59 0x07>;
			dma-names = "tx\0rx";
			pinctrl-names = "default\0sleep";
			pinctrl-0 = <0x62>;
			pinctrl-1 = <0x63>;
			#address-cells = <0x01>;
			#size-cells = <0x00>;
			status = "disabled";
		};

		spi@7af6000 {
			compatible = "qcom,spi-qup-v2.2.1";
			reg = <0x7af6000 0x600>;
			interrupts = <0x00 0x12c 0x04>;
			clock-names = "core\0iface";
			clocks = <0x02 0x40 0x02 0x3c>;
			dmas = <0x59 0x06 0x59 0x07>;
			dma-names = "tx\0rx";
			pinctrl-names = "default\0sleep";
			pinctrl-0 = <0x64>;
			pinctrl-1 = <0x65>;
			#address-cells = <0x01>;
			#size-cells = <0x00>;
			status = "disabled";
		};

		i2c@7af7000 {
			compatible = "qcom,i2c-qup-v2.2.1";
			reg = <0x7af7000 0x600>;
			interrupts = <0x00 0x12d 0x04>;
			clock-names = "core\0iface";
			clocks = <0x02 0x41 0x02 0x3c>;
			dmas = <0x59 0x08 0x59 0x09>;
			dma-names = "tx\0rx";
			pinctrl-names = "default\0sleep";
			pinctrl-0 = <0x66>;
			pinctrl-1 = <0x67>;
			#address-cells = <0x01>;
			#size-cells = <0x00>;
			status = "disabled";
		};

		spi@7af7000 {
			compatible = "qcom,spi-qup-v2.2.1";
			reg = <0x7af7000 0x600>;
			interrupts = <0x00 0x12d 0x04>;
			clock-names = "core\0iface";
			clocks = <0x02 0x42 0x02 0x3c>;
			dmas = <0x59 0x08 0x59 0x09>;
			dma-names = "tx\0rx";
			pinctrl-names = "default\0sleep";
			pinctrl-0 = <0x68>;
			pinctrl-1 = <0x69>;
			#address-cells = <0x01>;
			#size-cells = <0x00>;
			status = "disabled";
		};

		i2c@7af8000 {
			compatible = "qcom,i2c-qup-v2.2.1";
			reg = <0x7af8000 0x600>;
			interrupts = <0x00 0x12e 0x04>;
			clock-names = "core\0iface";
			clocks = <0x02 0x43 0x02 0x3c>;
			dmas = <0x59 0x0a 0x59 0x0b>;
			dma-names = "tx\0rx";
			pinctrl-names = "default\0sleep";
			pinctrl-0 = <0x6a>;
			pinctrl-1 = <0x6b>;
			#address-cells = <0x01>;
			#size-cells = <0x00>;
			status = "disabled";
		};

		remoteproc@a204000 {
			compatible = "qcom,pronto-v3-pil\0qcom,pronto";
			reg = <0xa204000 0x2000 0xa202000 0x1000 0xa21b000 0x3000>;
			reg-names = "ccu\0dxe\0pmu";
			memory-region = <0x6c>;
			interrupts-extended = <0x01 0x00 0x95 0x01 0x6d 0x00 0x01 0x6d 0x01 0x01 0x6d 0x02 0x01 0x6d 0x03 0x01>;
			interrupt-names = "wdog\0fatal\0ready\0handover\0stop-ack";
			power-domains = <0x34 0x02 0x34 0x05>;
			power-domain-names = "cx\0mx";
			qcom,smem-states = <0x6e 0x00>;
			qcom,smem-state-names = "stop";
			pinctrl-names = "default";
			pinctrl-0 = <0x6f>;
			status = "disabled";
			phandle = <0x70>;

			iris {
				clocks = <0x1b 0x10>;
				clock-names = "xo";
			};

			smd-edge {
				interrupts = <0x00 0x8e 0x01>;
				mboxes = <0x0e 0x11>;
				qcom,smd-edge = <0x06>;
				qcom,remote-pid = <0x04>;
				label = "pronto";

				wcnss {
					compatible = "qcom,wcnss";
					qcom,smd-channels = "WCNSS_CTRL";
					qcom,mmio = <0x70>;

					bluetooth {
						compatible = "qcom,wcnss-bt";
					};

					wifi {
						compatible = "qcom,wcnss-wlan";
						interrupts = <0x00 0x91 0x04 0x00 0x92 0x04>;
						interrupt-names = "tx\0rx";
						qcom,smem-states = <0x71 0x0a 0x71 0x09>;
						qcom,smem-state-names = "tx-enable\0tx-rings-empty";
					};
				};
			};
		};

		interrupt-controller@b000000 {
			compatible = "qcom,msm-qgic2";
			interrupt-controller;
			#interrupt-cells = <0x03>;
			reg = <0xb000000 0x1000 0xb002000 0x1000>;
			phandle = <0x01>;
		};

		mailbox@b011000 {
			compatible = "qcom,msm8953-apcs-kpss-global\0syscon";
			reg = <0xb011000 0x1000>;
			#mbox-cells = <0x01>;
			phandle = <0x0e>;
		};

		timer@b120000 {
			compatible = "arm,armv7-timer-mem";
			reg = <0xb120000 0x1000>;
			#address-cells = <0x01>;
			#size-cells = <0x01>;
			ranges;

			frame@b121000 {
				frame-number = <0x00>;
				interrupts = <0x00 0x08 0x04 0x00 0x07 0x04>;
				reg = <0xb121000 0x1000 0xb122000 0x1000>;
			};

			frame@b123000 {
				frame-number = <0x01>;
				interrupts = <0x00 0x09 0x04>;
				reg = <0xb123000 0x1000>;
				status = "disabled";
			};

			frame@b124000 {
				frame-number = <0x02>;
				interrupts = <0x00 0x0a 0x04>;
				reg = <0xb124000 0x1000>;
				status = "disabled";
			};

			frame@b125000 {
				frame-number = <0x03>;
				interrupts = <0x00 0x0b 0x04>;
				reg = <0xb125000 0x1000>;
				status = "disabled";
			};

			frame@b126000 {
				frame-number = <0x04>;
				interrupts = <0x00 0x0c 0x04>;
				reg = <0xb126000 0x1000>;
				status = "disabled";
			};

			frame@b127000 {
				frame-number = <0x05>;
				interrupts = <0x00 0x0d 0x04>;
				reg = <0xb127000 0x1000>;
				status = "disabled";
			};

			frame@b128000 {
				frame-number = <0x06>;
				interrupts = <0x00 0x0e 0x04>;
				reg = <0xb128000 0x1000>;
				status = "disabled";
			};
		};

		remoteproc@c200000 {
			compatible = "qcom,msm8953-adsp-pil";
			reg = <0xc200000 0x100>;
			interrupts-extended = <0x01 0x00 0x125 0x01 0x72 0x00 0x01 0x72 0x01 0x01 0x72 0x02 0x01 0x72 0x03 0x01>;
			interrupt-names = "wdog\0fatal\0ready\0handover\0stop-ack";
			clocks = <0x1b 0x00>;
			clock-names = "xo";
			power-domains = <0x34 0x02>;
			power-domain-names = "cx";
			memory-region = <0x73>;
			qcom,smem-states = <0x74 0x00>;
			qcom,smem-state-names = "stop";
			status = "disabled";

			smd-edge {
				interrupts = <0x00 0x121 0x01>;
				label = "lpass";
				mboxes = <0x0e 0x08>;
				qcom,smd-edge = <0x01>;
				qcom,remote-pid = <0x02>;

				apr {
					compatible = "qcom,apr-v2";
					qcom,smd-channels = "apr_audio_svc";
					qcom,domain = <0x04>;
					#address-cells = <0x01>;
					#size-cells = <0x00>;

					service@3 {
						reg = <0x03>;
						compatible = "qcom,q6core";
					};

					service@4 {
						compatible = "qcom,q6afe";
						reg = <0x04>;

						dais {
							compatible = "qcom,q6afe-dais";
							#address-cells = <0x01>;
							#size-cells = <0x00>;
							#sound-dai-cells = <0x01>;

							dai@16 {
								reg = <0x10>;
								qcom,sd-lines = <0x00 0x01>;
							};

							dai@20 {
								reg = <0x15>;
								qcom,sd-lines = <0x00 0x01>;
							};

							dai@127 {
								reg = <0x7f>;
								qcom,sd-lines = <0x00>;
							};
						};

						clock-controller {
							compatible = "qcom,q6afe-clocks";
							#clock-cells = <0x02>;
						};
					};

					service@7 {
						compatible = "qcom,q6asm";
						reg = <0x07>;

						dais {
							compatible = "qcom,q6asm-dais";
							#address-cells = <0x01>;
							#size-cells = <0x00>;
							#sound-dai-cells = <0x01>;

							dai@0 {
								reg = <0x00>;
								direction = <0x02>;
							};

							dai@1 {
								reg = <0x01>;
								direction = <0x01>;
							};

							dai@2 {
								reg = <0x02>;
								direction = <0x02>;
							};

							dai@3 {
								reg = <0x03>;
								direction = <0x02>;
								is-compress-dai;
							};
						};
					};

					service@8 {
						compatible = "qcom,q6adm";
						reg = <0x08>;

						routing {
							compatible = "qcom,q6adm-routing";
							#sound-dai-cells = <0x00>;
						};
					};
				};
			};
		};
	};

	thermal-zones {

		cpu0-thermal {
			polling-delay-passive = <0xfa>;
			thermal-sensors = <0x75 0x0d>;

			trips {

				trip-point0 {
					temperature = <0x13880>;
					hysteresis = <0x7d0>;
					type = "passive";
					phandle = <0x76>;
				};

				crit {
					temperature = <0x186a0>;
					hysteresis = <0x7d0>;
					type = "critical";
				};
			};

			cooling-maps {

				map0 {
					trip = <0x76>;
					cooling-device = <0x06 0xffffffff 0xffffffff 0x07 0xffffffff 0xffffffff 0x08 0xffffffff 0xffffffff 0x09 0xffffffff 0xffffffff>;
				};
			};
		};

		cpu4-thermal {
			polling-delay-passive = <0xfa>;
			thermal-sensors = <0x75 0x05>;

			trips {

				trip-point0 {
					temperature = <0x13880>;
					hysteresis = <0x7d0>;
					type = "passive";
					phandle = <0x77>;
				};

				crit {
					temperature = <0x186a0>;
					hysteresis = <0x7d0>;
					type = "critical";
				};
			};

			cooling-maps {

				map0 {
					trip = <0x77>;
					cooling-device = <0x0a 0xffffffff 0xffffffff>;
				};
			};
		};

		cpu5-thermal {
			polling-delay-passive = <0xfa>;
			thermal-sensors = <0x75 0x06>;

			trips {

				trip-point0 {
					temperature = <0x13880>;
					hysteresis = <0x7d0>;
					type = "passive";
					phandle = <0x78>;
				};

				crit {
					temperature = <0x186a0>;
					hysteresis = <0x7d0>;
					type = "critical";
				};
			};

			cooling-maps {

				map0 {
					trip = <0x78>;
					cooling-device = <0x0b 0xffffffff 0xffffffff>;
				};
			};
		};

		cpu6-thermal {
			polling-delay-passive = <0xfa>;
			thermal-sensors = <0x75 0x07>;

			trips {

				trip-point0 {
					temperature = <0x13880>;
					hysteresis = <0x7d0>;
					type = "passive";
					phandle = <0x79>;
				};

				crit {
					temperature = <0x186a0>;
					hysteresis = <0x7d0>;
					type = "critical";
				};
			};

			cooling-maps {

				map0 {
					trip = <0x79>;
					cooling-device = <0x0c 0xffffffff 0xffffffff>;
				};
			};
		};

		cpu7-thermal {
			polling-delay-passive = <0xfa>;
			thermal-sensors = <0x75 0x08>;

			trips {

				trip-point0 {
					temperature = <0x13880>;
					hysteresis = <0x7d0>;
					type = "passive";
					phandle = <0x7a>;
				};

				crit {
					temperature = <0x186a0>;
					hysteresis = <0x7d0>;
					type = "critical";
				};
			};

			cooling-maps {

				map0 {
					trip = <0x7a>;
					cooling-device = <0x0d 0xffffffff 0xffffffff>;
				};
			};
		};

		gpu-thermal {
			polling-delay-passive = <0xfa>;
			thermal-sensors = <0x75 0x0f>;

			trips {

				trip-point0 {
					temperature = <0x11170>;
					hysteresis = <0x7d0>;
					type = "passive";
					phandle = <0x7b>;
				};

				crit {
					temperature = <0x15f90>;
					hysteresis = <0x7d0>;
					type = "critical";
				};
			};

			cooling-maps {

				map0 {
					trip = <0x7b>;
					cooling-device = <0x7c 0xffffffff 0xffffffff>;
				};
			};
		};

		pm8953-thermal {
			thermal-sensors = <0x7d>;

			trips {

				trip0 {
					temperature = <0x19a28>;
					hysteresis = <0x00>;
					type = "passive";
				};

				trip1 {
					temperature = <0x1e848>;
					hysteresis = <0x00>;
					type = "hot";
				};

				trip2 {
					temperature = <0x23668>;
					hysteresis = <0x00>;
					type = "critical";
				};
			};
		};
	};

	timer {
		compatible = "arm,armv8-timer";
		interrupts = <0x01 0x02 0xff08 0x01 0x03 0xff08 0x01 0x04 0xff08 0x01 0x01 0xff08>;
	};

	backlight {
		compatible = "led-backlight";
		leds = <0x7e>;
	};

	gpio-keys {
		compatible = "gpio-keys";
		pinctrl-names = "default";
		pinctrl-0 = <0x7f>;

		key-volume-up {
			label = "Volume Up";
			gpios = <0x1a 0x55 0x01>;
			linux,code = <0x73>;
		};
	};

	vph-pwr-regulator {
		compatible = "regulator-fixed";
		regulator-name = "vph_pwr";
		regulator-always-on;
		regulator-boot-on;
		phandle = <0x13>;
	};
};
